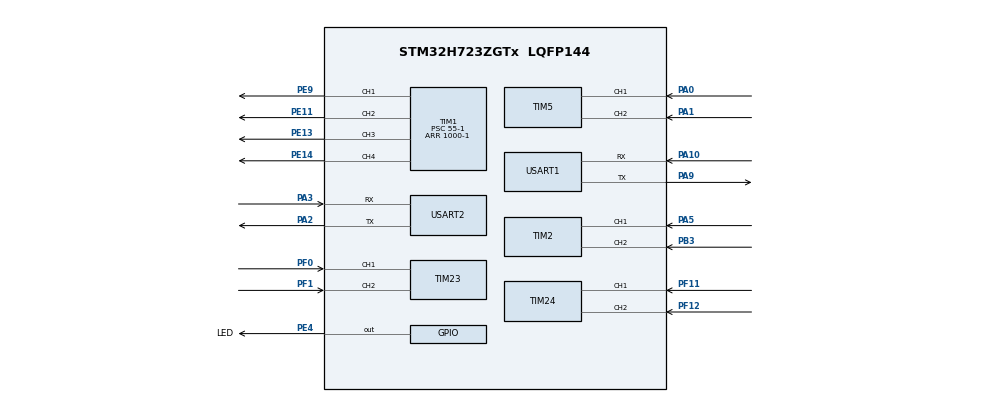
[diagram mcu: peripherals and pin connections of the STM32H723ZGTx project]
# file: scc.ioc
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CORTEX_M7.default_mode_Activation=1
FREERTOS.Tasks01=TaskSafety,47,512,TaskSafetyEntry,As weak,NULL,Dynamic,NULL,NULL;TaskLed,24,512,TaskLedEntry,As weak,NULL,Dynamic,NULL,NULL;TaskEncoder,46,512,TaskEncoderEntry,As weak,NULL,Dynamic,NULL,NULL;TaskCtrl,46,1024,TaskCtrlEntry,As weak,NULL,Dynamic,NULL,NULL;TaskComm,45,2048,TaskCommEntry,As weak,NULL,Dynamic,NULL,NULL;TaskCalculate,44,2048,TaskCalculateEntry,As weak,NULL,Dynamic,NULL,NULL;TaskLog,42,2048,TaskLogEntry,As weak,NULL,Dynamic,NULL,NULL;Task_ensor,43,2048,TaskSensorEntry,As weak,NULL,Dynamic,NULL,NULL
FREERTOS.configTOTAL_HEAP_SIZE=81920
Mcu.Family=STM32H7
Mcu.Name=STM32H723ZGTx
Mcu.Package=LQFP144
NVIC.PriorityGroup=NVIC_PRIORITYGROUP_4
NVIC.TIM6_DAC_IRQn=true\:15\:0\:false\:false\:true\:false\:false\:true\:true
NVIC.TimeBase=TIM6_DAC_IRQn
NVIC.TimeBaseIP=TIM6
NVIC.USART1_IRQn=true\:14\:0\:true\:false\:true\:true\:true\:true\:true
NVIC.USART2_IRQn=true\:10\:0\:true\:false\:true\:true\:true\:true\:true
PA0.Signal=S_TIM5_CH1
PA1.Signal=S_TIM5_CH2
PA10.Mode=Asynchronous
PA10.Signal=USART1_RX
PA13(JTMS/SWDIO).Mode=Serial_Wire
PA13(JTMS/SWDIO).Signal=DEBUG_JTMS-SWDIO
PA14(JTCK/SWCLK).Mode=Serial_Wire
PA14(JTCK/SWCLK).Signal=DEBUG_JTCK-SWCLK
PA2.Mode=Asynchronous
PA2.Signal=USART2_TX
PA3.Mode=Asynchronous
PA3.Signal=USART2_RX
PA5.Signal=S_TIM2_CH1_ETR
PA9.Mode=Asynchronous
PA9.Signal=USART1_TX
PB3(JTDO/TRACESWO).Signal=S_TIM2_CH2
PC14-OSC32_IN.Mode=LSE-External-Oscillator
PC14-OSC32_IN.Signal=RCC_OSC32_IN
PC15-OSC32_OUT.Mode=LSE-External-Oscillator
PC15-OSC32_OUT.Signal=RCC_OSC32_OUT
PE11.Signal=S_TIM1_CH2
PE13.Signal=S_TIM1_CH3
PE14.Signal=S_TIM1_CH4
PE4.GPIO_Label=LED
PE4.PinState=GPIO_PIN_SET
PE4.Signal=GPIO_Output
PE9.Signal=S_TIM1_CH1
PF0.Mode=Encoder_Interface
PF0.Signal=TIM23_CH1
PF1.Signal=S_TIM23_CH2
PF11.Mode=Encoder_Interface
PF11.Signal=TIM24_CH1
PF12.Signal=S_TIM24_CH2
PH0-OSC_IN.Mode=HSE-External-Oscillator
PH0-OSC_IN.Signal=RCC_OSC_IN
PH1-OSC_OUT.Mode=HSE-External-Oscillator
PH1-OSC_OUT.Signal=RCC_OSC_OUT
ProjectManager.HeapSize=0x200
ProjectManager.StackSize=0x400
ProjectManager.TargetToolchain=CMake
RCC.ADCFreq_Value=50390625
RCC.APB1Freq_Value=137500000
RCC.APB2Freq_Value=137500000
RCC.APB3Freq_Value=137500000
RCC.APB4Freq_Value=137500000
RCC.CortexFreq_Value=550000000
RCC.D1PPRE=RCC_APB3_DIV2
RCC.D2PPRE1=RCC_APB1_DIV2
RCC.D2PPRE2=RCC_APB2_DIV2
RCC.D3PPRE=RCC_APB4_DIV2
RCC.DIVM1=2
RCC.DIVN1=44
RCC.DIVP1=1
RCC.HCLKFreq_Value=275000000
RCC.HPRE=RCC_HCLK_DIV2
RCC.PLL2FRACN=0
RCC.PLL3FRACN=0
RCC.PLL3_VCI_Range-AdvancedSettings=RCC_PLL3VCIRANGE_3
RCC.PLLFRACN=0
RCC.PLLSourceVirtual=RCC_PLLSOURCE_HSE
RCC.SYSCLKFreq_VALUE=550000000
RCC.SYSCLKSource=RCC_SYSCLKSOURCE_PLLCLK
RCC.USBFreq_Value=275000000
SH.S_TIM1_CH1.0=TIM1_CH1,PWM Generation1 CH1
SH.S_TIM1_CH2.0=TIM1_CH2,PWM Generation2 CH2
SH.S_TIM1_CH3.0=TIM1_CH3,PWM Generation3 CH3
SH.S_TIM1_CH4.0=TIM1_CH4,PWM Generation4 CH4
SH.S_TIM23_CH2.0=TIM23_CH2,Encoder_Interface
SH.S_TIM24_CH2.0=TIM24_CH2,Encoder_Interface
SH.S_TIM2_CH1_ETR.0=TIM2_CH1,Encoder_Interface
SH.S_TIM2_CH2.0=TIM2_CH2,Encoder_Interface
SH.S_TIM5_CH1.0=TIM5_CH1,Encoder_Interface
SH.S_TIM5_CH2.0=TIM5_CH2,Encoder_Interface
TIM1.Channel-PWM\ Generation1\ CH1=TIM_CHANNEL_1
TIM1.Channel-PWM\ Generation2\ CH2=TIM_CHANNEL_2
TIM1.Channel-PWM\ Generation3\ CH3=TIM_CHANNEL_3
TIM1.Channel-PWM\ Generation4\ CH4=TIM_CHANNEL_4
TIM1.Period=1000-1
TIM1.Prescaler=55-1
TIM2.EncoderMode=TIM_ENCODERMODE_TI12
TIM23.EncoderMode=TIM_ENCODERMODE_TI12
TIM24.EncoderMode=TIM_ENCODERMODE_TI12
TIM5.EncoderMode=TIM_ENCODERMODE_TI12
TIM5.IC1Filter=0
TIM5.IC2Filter=0
USART1.VirtualMode-Asynchronous=VM_ASYNC
USART2.VirtualMode-Asynchronous=VM_ASYNC
VP_FREERTOS_VS_CMSIS_V2.Mode=CMSIS_V2
VP_MEMORYMAP_VS_MEMORYMAP.Mode=CurAppReg
VP_SYS_VS_tim6.Mode=TIM6
board=custom

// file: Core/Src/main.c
/* USER CODE BEGIN Header */
/**
 ******************************************************************************
 * @file           : main.c
 * @brief          : Main program body
 ******************************************************************************
 * @attention
 *
 * Copyright (c) 2025 STMicroelectronics.
 * All rights reserved.
 *
 * This software is licensed under terms that can be found in the LICENSE file
 * in the root directory of this software component.
 * If no LICENSE file comes with this software, it is provided AS-IS.
 *
 ******************************************************************************
 */
/* USER CODE END Header */
#include "main.h"
#include "cmsis_os.h"
#include "tim.h"
#include "usart.h"
#include "gpio.h"

/* USER CODE BEGIN Includes */
#include "task_entry.h"
/* USER CODE END Includes */

void SystemClock_Config(void);
static void MPU_Config(void);
void MX_FREERTOS_Init(void);

int main(void)
{

  /* MPU Configuration--------------------------------------------------------*/
  MPU_Config();

  /* MCU Configuration--------------------------------------------------------*/

  /* Reset of all peripherals, Initializes the Flash interface and the Systick. */
  HAL_Init();

  /* Configure the system clock */
  SystemClock_Config();

  /* USER CODE BEGIN SysInit */

  TaskEntry();
  /* USER CODE END SysInit */

  /* Initialize all configured peripherals */
  MX_GPIO_Init();
  MX_USART1_UART_Init();
  MX_TIM2_Init();
  MX_TIM1_Init();
  MX_TIM5_Init();
  MX_TIM23_Init();
  MX_TIM24_Init();
  MX_USART2_UART_Init();

  /* Init scheduler */
  osKernelInitialize();  /* Call init function for freertos objects (in cmsis_os2.c) */
  MX_FREERTOS_Init();

  /* Start scheduler */
  osKernelStart();

  /* We should never get here as control is now taken by the scheduler */

  /* Infinite loop */
  /* USER CODE BEGIN WHILE */
    uint8_t msg[] = "Hello World\r\n";
    while (1)
    {
        Led_Ctrl(LED_ON);
        HAL_Delay(500);
        Led_Ctrl(LED_OFF);
        HAL_Delay(500);
        HAL_UART_Transmit_IT(&huart1, msg, sizeof(msg) - 1);

    /* USER CODE END WHILE */

    }
}

void SystemClock_Config(void)
{
  RCC_OscInitTypeDef RCC_OscInitStruct = {0};
  RCC_ClkInitTypeDef RCC_ClkInitStruct = {0};

  /** Supply configuration update enable
  */
  HAL_PWREx_ConfigSupply(PWR_LDO_SUPPLY);

  /** Configure the main internal regulator output voltage
  */
  __HAL_PWR_VOLTAGESCALING_CONFIG(PWR_REGULATOR_VOLTAGE_SCALE0);

  while(!__HAL_PWR_GET_FLAG(PWR_FLAG_VOSRDY)) {}

  /** Initializes the RCC Oscillators according to the specified parameters
  * in the RCC_OscInitTypeDef structure.
  */
  RCC_OscInitStruct.OscillatorType = RCC_OSCILLATORTYPE_HSE;
  RCC_OscInitStruct.HSEState = RCC_HSE_ON;
  RCC_OscInitStruct.PLL.PLLState = RCC_PLL_ON;
  RCC_OscInitStruct.PLL.PLLSource = RCC_PLLSOURCE_HSE;
  RCC_OscInitStruct.PLL.PLLM = 2;
  RCC_OscInitStruct.PLL.PLLN = 44;
  RCC_OscInitStruct.PLL.PLLP = 1;
  RCC_OscInitStruct.PLL.PLLQ = 2;
  RCC_OscInitStruct.PLL.PLLR = 2;
  RCC_OscInitStruct.PLL.PLLRGE = RCC_PLL1VCIRANGE_3;
  RCC_OscInitStruct.PLL.PLLVCOSEL = RCC_PLL1VCOWIDE;
  RCC_OscInitStruct.PLL.PLLFRACN = 0;
  if (HAL_RCC_OscConfig(&RCC_OscInitStruct) != HAL_OK)
  {
    Error_Handler();
  }

  /** Initializes the CPU, AHB and APB buses clocks
  */
  RCC_ClkInitStruct.ClockType = RCC_CLOCKTYPE_HCLK|RCC_CLOCKTYPE_SYSCLK
                              |RCC_CLOCKTYPE_PCLK1|RCC_CLOCKTYPE_PCLK2
                              |RCC_CLOCKTYPE_D3PCLK1|RCC_CLOCKTYPE_D1PCLK1;
  RCC_ClkInitStruct.SYSCLKSource = RCC_SYSCLKSOURCE_PLLCLK;
  RCC_ClkInitStruct.SYSCLKDivider = RCC_SYSCLK_DIV1;
  RCC_ClkInitStruct.AHBCLKDivider = RCC_HCLK_DIV2;
  RCC_ClkInitStruct.APB3CLKDivider = RCC_APB3_DIV2;
  RCC_ClkInitStruct.APB1CLKDivider = RCC_APB1_DIV2;
  RCC_ClkInitStruct.APB2CLKDivider = RCC_APB2_DIV2;
  RCC_ClkInitStruct.APB4CLKDivider = RCC_APB4_DIV2;

  if (HAL_RCC_ClockConfig(&RCC_ClkInitStruct, FLASH_LATENCY_3) != HAL_OK)
  {
    Error_Handler();
  }
}

 /* MPU Configuration */

void MPU_Config(void)
{
  MPU_Region_InitTypeDef MPU_InitStruct = {0};

  /* Disables the MPU */
  HAL_MPU_Disable();

  /** Initializes and configures the Region and the memory to be protected
  */
  MPU_InitStruct.Enable = MPU_REGION_ENABLE;
  MPU_InitStruct.Number = MPU_REGION_NUMBER0;
  MPU_InitStruct.BaseAddress = 0x0;
  MPU_InitStruct.Size = MPU_REGION_SIZE_4GB;
  MPU_InitStruct.SubRegionDisable = 0x87;
  MPU_InitStruct.TypeExtField = MPU_TEX_LEVEL0;
  MPU_InitStruct.AccessPermission = MPU_REGION_NO_ACCESS;
  MPU_InitStruct.DisableExec = MPU_INSTRUCTION_ACCESS_DISABLE;
  MPU_InitStruct.IsShareable = MPU_ACCESS_SHAREABLE;
  MPU_InitStruct.IsCacheable = MPU_ACCESS_NOT_CACHEABLE;
  MPU_InitStruct.IsBufferable = MPU_ACCESS_NOT_BUFFERABLE;

  HAL_MPU_ConfigRegion(&MPU_InitStruct);
  /* Enables the MPU */
  HAL_MPU_Enable(MPU_PRIVILEGED_DEFAULT);

}

void HAL_TIM_PeriodElapsedCallback(TIM_HandleTypeDef *htim)
{
  if (htim->Instance == TIM6)
  {
    HAL_IncTick();
  }
}

void Error_Handler(void)
{
    __disable_irq();
    while (1)
    {
    }
}

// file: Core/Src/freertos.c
/* USER CODE BEGIN Header */
/**
  ******************************************************************************
  * File Name          : freertos.c
  * Description        : Code for freertos applications
  ******************************************************************************
  * @attention
  *
  * Copyright (c) 2025 STMicroelectronics.
  * All rights reserved.
  *
  * This software is licensed under terms that can be found in the LICENSE file
  * in the root directory of this software component.
  * If no LICENSE file comes with this software, it is provided AS-IS.
  *
  ******************************************************************************
  */
/* USER CODE END Header */

#include "FreeRTOS.h"
#include "task.h"
#include "main.h"
#include "cmsis_os.h"

/* Definitions for TaskSafety */
osThreadId_t TaskSafetyHandle;
const osThreadAttr_t TaskSafety_attributes = {
  .name = "TaskSafety",
  .stack_size = 512 * 4,
  .priority = (osPriority_t) osPriorityHigh7,
};
/* Definitions for TaskLed */
osThreadId_t TaskLedHandle;
const osThreadAttr_t TaskLed_attributes = {
  .name = "TaskLed",
  .stack_size = 512 * 4,
  .priority = (osPriority_t) osPriorityNormal,
};
/* Definitions for TaskEncoder */
osThreadId_t TaskEncoderHandle;
const osThreadAttr_t TaskEncoder_attributes = {
  .name = "TaskEncoder",
  .stack_size = 512 * 4,
  .priority = (osPriority_t) osPriorityHigh6,
};
/* Definitions for TaskCtrl */
osThreadId_t TaskCtrlHandle;
const osThreadAttr_t TaskCtrl_attributes = {
  .name = "TaskCtrl",
  .stack_size = 1024 * 4,
  .priority = (osPriority_t) osPriorityHigh6,
};
/* Definitions for TaskComm */
osThreadId_t TaskCommHandle;
const osThreadAttr_t TaskComm_attributes = {
  .name = "TaskComm",
  .stack_size = 2048 * 4,
  .priority = (osPriority_t) osPriorityHigh5,
};
/* Definitions for TaskCalculate */
osThreadId_t TaskCalculateHandle;
const osThreadAttr_t TaskCalculate_attributes = {
  .name = "TaskCalculate",
  .stack_size = 2048 * 4,
  .priority = (osPriority_t) osPriorityHigh4,
};
/* Definitions for TaskLog */
osThreadId_t TaskLogHandle;
const osThreadAttr_t TaskLog_attributes = {
  .name = "TaskLog",
  .stack_size = 2048 * 4,
  .priority = (osPriority_t) osPriorityHigh2,
};
/* Definitions for Task_ensor */
osThreadId_t Task_ensorHandle;
const osThreadAttr_t Task_ensor_attributes = {
  .name = "Task_ensor",
  .stack_size = 2048 * 4,
  .priority = (osPriority_t) osPriorityHigh3,
};

void TaskSafetyEntry(void *argument);
void TaskLedEntry(void *argument);
void TaskEncoderEntry(void *argument);
void TaskCtrlEntry(void *argument);
void TaskCommEntry(void *argument);
void TaskCalculateEntry(void *argument);
void TaskLogEntry(void *argument);
void TaskSensorEntry(void *argument);

void MX_FREERTOS_Init(void); /* (MISRA C 2004 rule 8.1) */

void MX_FREERTOS_Init(void) {

  /* Create the thread(s) */
  /* creation of TaskSafety */
  TaskSafetyHandle = osThreadNew(TaskSafetyEntry, NULL, &TaskSafety_attributes);

  /* creation of TaskLed */
  TaskLedHandle = osThreadNew(TaskLedEntry, NULL, &TaskLed_attributes);

  /* creation of TaskEncoder */
  TaskEncoderHandle = osThreadNew(TaskEncoderEntry, NULL, &TaskEncoder_attributes);

  /* creation of TaskCtrl */
  TaskCtrlHandle = osThreadNew(TaskCtrlEntry, NULL, &TaskCtrl_attributes);

  /* creation of TaskComm */
  TaskCommHandle = osThreadNew(TaskCommEntry, NULL, &TaskComm_attributes);

  /* creation of TaskCalculate */
  TaskCalculateHandle = osThreadNew(TaskCalculateEntry, NULL, &TaskCalculate_attributes);

  /* creation of TaskLog */
  TaskLogHandle = osThreadNew(TaskLogEntry, NULL, &TaskLog_attributes);

  /* creation of Task_ensor */
  Task_ensorHandle = osThreadNew(TaskSensorEntry, NULL, &Task_ensor_attributes);

}

__weak void TaskSafetyEntry(void *argument)
{
  for(;;)
  {
    osDelay(1);
  }
}

__weak void TaskLedEntry(void *argument)
{
  for(;;)
  {
    osDelay(1);
  }
}

__weak void TaskEncoderEntry(void *argument)
{
  for(;;)
  {
    osDelay(1);
  }
}

__weak void TaskCtrlEntry(void *argument)
{
  for(;;)
  {
    osDelay(1);
  }
}

__weak void TaskCommEntry(void *argument)
{
  for(;;)
  {
    osDelay(1);
  }
}

__weak void TaskCalculateEntry(void *argument)
{
  for(;;)
  {
    osDelay(1);
  }
}

__weak void TaskLogEntry(void *argument)
{
  for(;;)
  {
    osDelay(1);
  }
}

__weak void TaskSensorEntry(void *argument)
{
  for(;;)
  {
    osDelay(1);
  }
}
